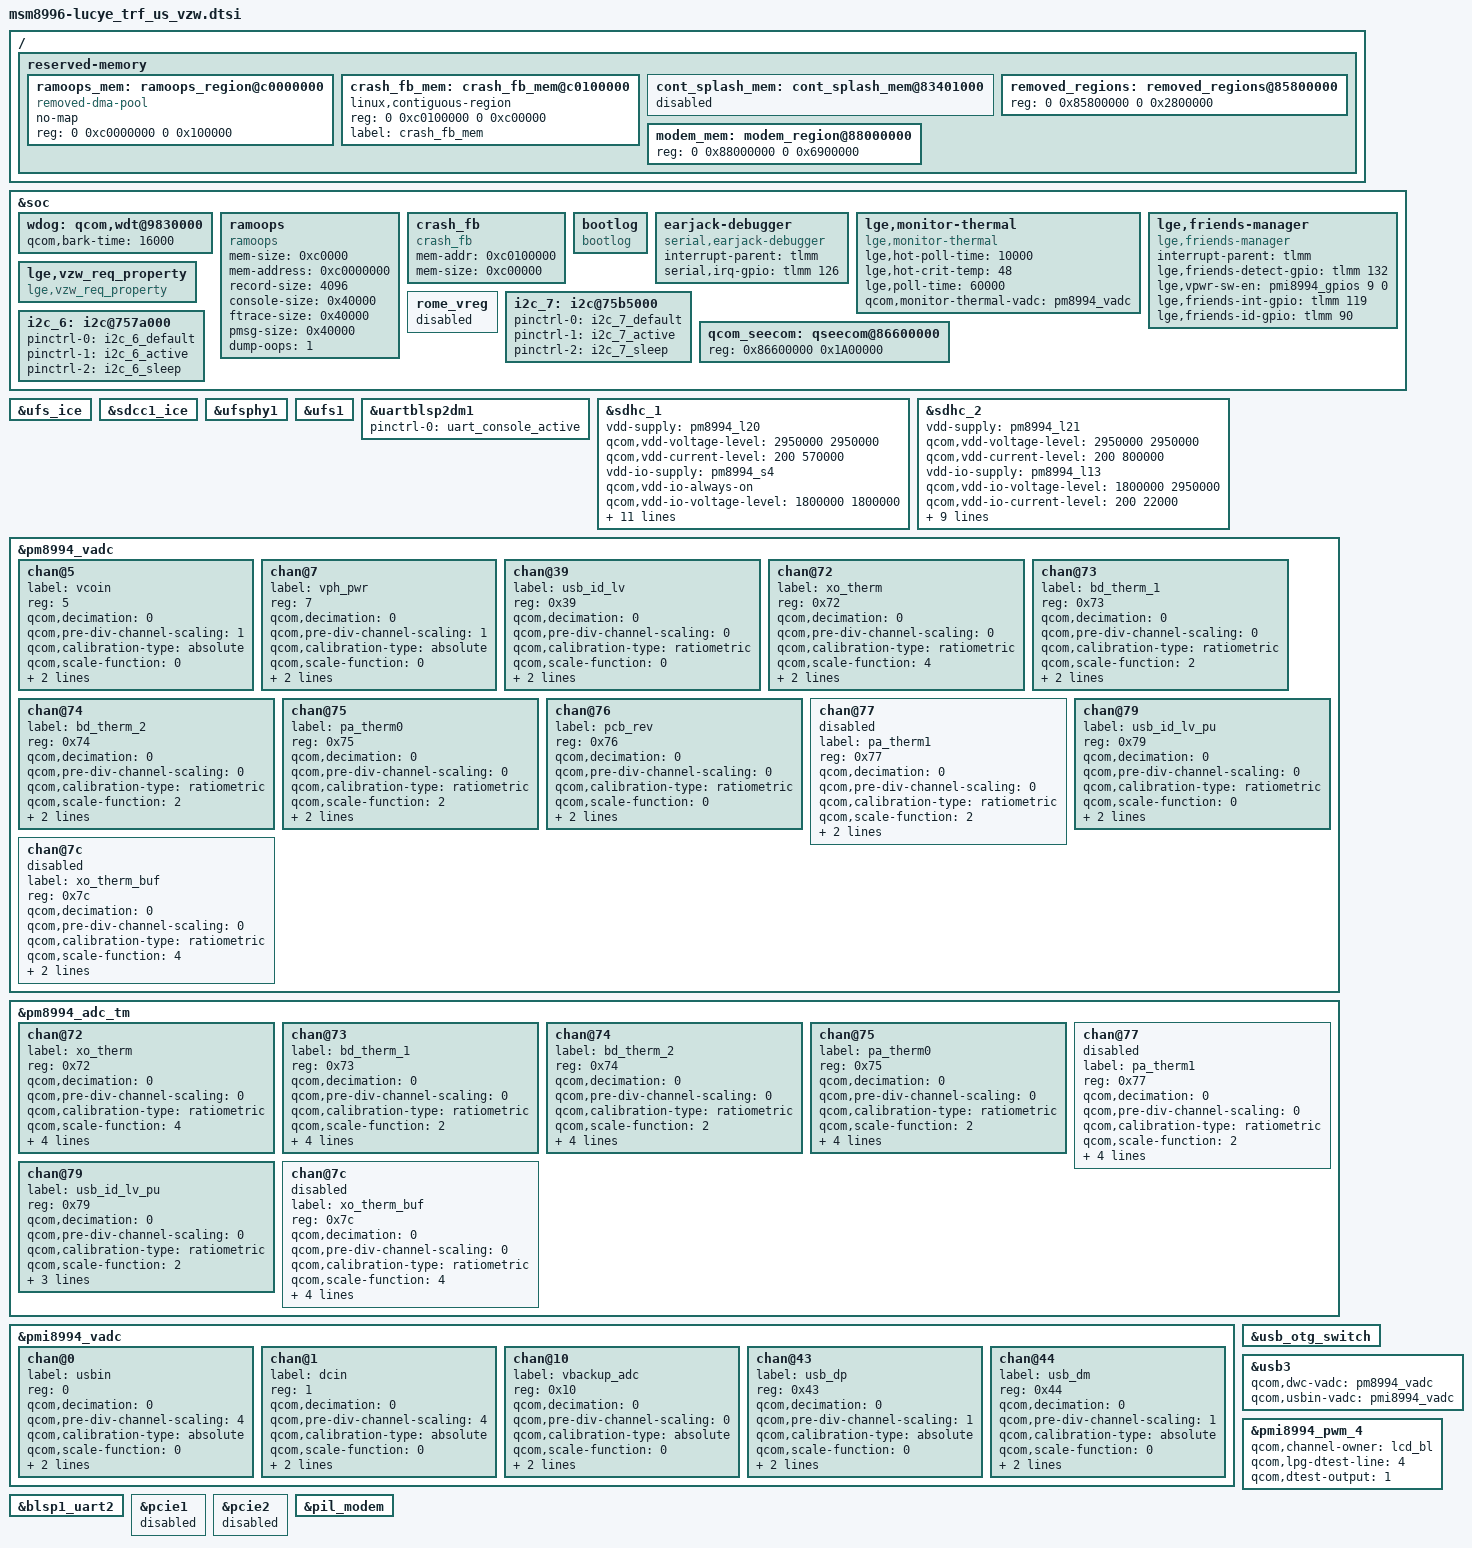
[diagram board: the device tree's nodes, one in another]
/* Copyright (c) 2015, The Linux Foundation. All rights reserved.
 *
 * This program is free software; you can redistribute it and/or modify
 * it under the terms of the GNU General Public License version 2 and
 * only version 2 as published by the Free Software Foundation.
 *
 * This program is distributed in the hope that it will be useful,
 * but WITHOUT ANY WARRANTY; without even the implied warranty of
 * MERCHANTABILITY or FITNESS FOR A PARTICULAR PURPOSE.  See the
 * GNU General Public License for more details.
 */

#include "msm8996-lucye_trf_us_vzw-pinctrl.dtsi"
#include "msm8996-lucye_trf_us_vzw-misc.dtsi"
#include "msm8996-lucye_trf_us_vzw-panel.dtsi"
#include "msm8996-lucye_trf_us_vzw-pm.dtsi"
#include "msm8996-lucye_trf_us_vzw-connectivity.dtsi"
#include "msm8996-lucye_trf_us_vzw-nfc.dtsi"
#include "msm8996-lucye_trf_us_vzw-hdmi.dtsi"
#include "msm8996-lucye_trf_us_vzw-fingerprint.dtsi"
#include "msm8996-lucye_trf_us_vzw-usb.dtsi"

/ {
	reserved-memory {
		ramoops_mem: ramoops_region@c0000000 {
			compatible = "removed-dma-pool";
			no-map;
			reg = <0 0xc0000000 0 0x100000>;
		};

		crash_fb_mem: crash_fb_mem@c0100000 {
			linux,contiguous-region;
			reg = <0 0xc0100000 0 0xc00000>;
			label = "crash_fb_mem";
		};

		cont_splash_mem: cont_splash_mem@83401000 {
			status = "disabled";
		};

		/delete-node/ dfps_data_mem@83400000;

		removed_regions: removed_regions@85800000 {
			reg = <0 0x85800000 0 0x2800000>;
		};

		modem_mem: modem_region@88000000 {
			reg = <0 0x88000000 0 0x6900000>;
		};
	};
};

&soc {
	wdog: qcom,wdt@9830000 {
		qcom,bark-time = <16000>;
	};

	ramoops {
		compatible = "ramoops";
		mem-size = <0xc0000>;
		mem-address = <0xc0000000>;
		record-size = <4096>;
		console-size = <0x40000>;
		ftrace-size = <0x40000>;
		pmsg-size = <0x40000>;
		dump-oops = <1>;
	};

	crash_fb {
		compatible = "crash_fb";
		mem-addr = <0xc0100000>;
		mem-size = <0xc00000>;
	};

	bootlog {
		compatible = "bootlog";
	};

	earjack-debugger {
		compatible = "serial,earjack-debugger";
		status = "ok";
		interrupt-parent = <&tlmm>;
		serial,irq-gpio = <&tlmm 126 0>;
	};

	lge,monitor-thermal {
		compatible = "lge,monitor-thermal";
		status = "ok";
		lge,hot-poll-time = <10000>;
		lge,hot-crit-temp = <48>;
		lge,poll-time = <60000>;
		qcom,monitor-thermal-vadc = <&pm8994_vadc>;
	};


	lge,friends-manager {
		compatible = "lge,friends-manager";
		status = "ok";
		interrupt-parent = <&tlmm>;
		lge,friends-detect-gpio = <&tlmm 132 0>;
		lge,vpwr-sw-en = <&pmi8994_gpios 9 0>;
		lge,friends-int-gpio = <&tlmm 119 0>;
		lge,friends-id-gpio = <&tlmm 90 0>;
//		pinctrl-names = "friends_active_pins","friends_sleep_pins";
//		pinctrl-0 = <&friends_detect_active>;
//		pinctrl-1 = <&friends_detect_sleep>;
	};

	lge,vzw_req_property {
		compatible = "lge,vzw_req_property";
		status = "ok";
	};

	rome_vreg: rome_vreg {
		status = "disabled";
	};

	/* I2C configuration */
/*	i2c_12: i2c@75ba000 {
		pinctrl-names = "default", "i2c_sleep";
		pinctrl-0 = <&i2c_12_default>;
		pinctrl-1 = <&i2c_12_sleep>;
	};
*/
	i2c_7: i2c@75b5000 {
		pinctrl-names = "default", "i2c_active", "i2c_sleep";
		pinctrl-0 = <&i2c_7_default>;
		pinctrl-1 = <&i2c_7_active>;
		pinctrl-2 = <&i2c_7_sleep>;
	};

	i2c_6: i2c@757a000 {
		pinctrl-names = "default", "i2c_active", "i2c_sleep";
		pinctrl-0 = <&i2c_6_default>;
		pinctrl-1 = <&i2c_6_active>;
		pinctrl-2 = <&i2c_6_sleep>;
	};

	/*delete QCT finger */
	/delete-node/ qcom,qbt1000;

	/delete-node/ qcom,cnss;
	/delete-node/ qcom,wil6210;

	qcom_seecom: qseecom@86600000 {
		reg = <0x86600000 0x1A00000>;
	};

};

&ufs_ice {
	status = "ok";
};

&sdcc1_ice {
        status = "ok";
};

&ufsphy1 {
	status = "ok";
};

&ufs1 {
	status = "ok";
};

&uartblsp2dm1 {
	status = "ok";
	pinctrl-names = "default";
	pinctrl-0 = <&uart_console_active>;
};

&sdhc_1 {
	vdd-supply = <&pm8994_l20>;
	qcom,vdd-voltage-level = <2950000 2950000>;
	qcom,vdd-current-level = <200 570000>;

	vdd-io-supply = <&pm8994_s4>;
	qcom,vdd-io-always-on;
	qcom,vdd-io-voltage-level = <1800000 1800000>;
	qcom,vdd-io-current-level = <110 325000>;

	pinctrl-names = "active", "sleep";
	pinctrl-0 = <&sdc1_clk_on &sdc1_cmd_on &sdc1_data_on &sdc1_rclk_on>;
	pinctrl-1 = <&sdc1_clk_off &sdc1_cmd_off &sdc1_data_off &sdc1_rclk_off>;

	qcom,clk-rates = <400000 20000000 25000000 50000000 96000000 192000000 384000000>;
	qcom,ice-clk-rates = <300000000>;
	qcom,nonremovable;
	qcom,bus-speed-mode = "HS400_1p8v", "HS200_1p8v", "DDR_1p8v";

	status = "ok";
};

&sdhc_2 {
	vdd-supply = <&pm8994_l21>;
	qcom,vdd-voltage-level = <2950000 2950000>;
	qcom,vdd-current-level = <200 800000>;

	vdd-io-supply = <&pm8994_l13>;
	qcom,vdd-io-voltage-level = <1800000 2950000>;
	qcom,vdd-io-current-level = <200 22000>;

	pinctrl-names = "active", "sleep";
	pinctrl-0 = <&sdc2_clk_on  &sdc2_cmd_on &sdc2_data_on &sdc2_cd_on>;
	pinctrl-1 = <&sdc2_clk_off &sdc2_cmd_off &sdc2_data_off &sdc2_cd_off>;

	qcom,clk-rates = <400000 20000000 25000000 50000000 100000000 200000000>;
	qcom,bus-speed-mode = "SDR12", "SDR25", "SDR50", "DDR50", "SDR104";

	/* Though Active-Low-H/W-logic is actually adopted in circuit-diagram,
	Logic-value is reversed in 3in2-socket not in 2in1-socket.
	1: Active-Low, 0: Active-High
	*/
	cd-gpios = <&tlmm 95 0x0>;

	status = "ok";
};

&pm8994_vadc {
	chan@5 {
		label = "vcoin";
		reg = <5>;
		qcom,decimation = <0>;
		qcom,pre-div-channel-scaling = <1>;
		qcom,calibration-type = "absolute";
		qcom,scale-function = <0>;
		qcom,hw-settle-time = <0>;
		qcom,fast-avg-setup = <0>;
	};

	chan@7 {
		label = "vph_pwr";
		reg = <7>;
		qcom,decimation = <0>;
		qcom,pre-div-channel-scaling = <1>;
		qcom,calibration-type = "absolute";
		qcom,scale-function = <0>;
		qcom,hw-settle-time = <0>;
		qcom,fast-avg-setup = <0>;
	};

	chan@39 {
		label = "usb_id_lv";
		reg = <0x39>;
		qcom,decimation = <0>;
		qcom,pre-div-channel-scaling = <0>;
		qcom,calibration-type = "ratiometric";
		qcom,scale-function = <0>;
		qcom,hw-settle-time = <5>;
		qcom,fast-avg-setup = <0>;
	};

        chan@72 {
		label = "xo_therm";
		reg = <0x72>;
		qcom,decimation = <0>;
		qcom,pre-div-channel-scaling = <0>;
		qcom,calibration-type = "ratiometric";
		qcom,scale-function = <4>;
		qcom,hw-settle-time = <2>;
		qcom,fast-avg-setup = <0>;
		status = "ok";
	};

	chan@73 {
		label = "bd_therm_1";
		reg = <0x73>;
		qcom,decimation = <0>;
		qcom,pre-div-channel-scaling = <0>;
		qcom,calibration-type = "ratiometric";
		qcom,scale-function = <2>;
		qcom,hw-settle-time = <2>;
		qcom,fast-avg-setup = <0>;
		status = "ok";
	};

	chan@74 {
		label = "bd_therm_2";
		reg = <0x74>;
		qcom,decimation = <0>;
		qcom,pre-div-channel-scaling = <0>;
		qcom,calibration-type = "ratiometric";
		qcom,scale-function = <2>;
		qcom,hw-settle-time = <2>;
		qcom,fast-avg-setup = <0>;
		status = "ok";
	};

	chan@75 {
		label = "pa_therm0";
		reg = <0x75>;
		qcom,decimation = <0>;
		qcom,pre-div-channel-scaling = <0>;
		qcom,calibration-type = "ratiometric";
		qcom,scale-function = <2>;
		qcom,hw-settle-time = <2>;
		qcom,fast-avg-setup = <0>;
		status = "ok";
	};

	chan@76 {
		label = "pcb_rev";
		reg = <0x76>;
		qcom,decimation = <0>;
		qcom,pre-div-channel-scaling = <0>;
		qcom,calibration-type = "ratiometric";
		qcom,scale-function = <0>;
		qcom,hw-settle-time = <1>;
		qcom,fast-avg-setup = <0>;
	};

	chan@77 {
		label = "pa_therm1";
		reg = <0x77>;
		qcom,decimation = <0>;
		qcom,pre-div-channel-scaling = <0>;
		qcom,calibration-type = "ratiometric";
		qcom,scale-function = <2>;
		qcom,hw-settle-time = <2>;
		qcom,fast-avg-setup = <0>;
		status = "disabled";
	};

	chan@79 {
		label = "usb_id_lv_pu";
		reg = <0x79>;
		qcom,decimation = <0>;
		qcom,pre-div-channel-scaling = <0>;
		qcom,calibration-type = "ratiometric";
		qcom,scale-function = <0>;
		qcom,hw-settle-time = <5>;
		qcom,fast-avg-setup = <0>;
	};

	chan@7c {
		label = "xo_therm_buf";
		reg = <0x7c>;
		qcom,decimation = <0>;
		qcom,pre-div-channel-scaling = <0>;
		qcom,calibration-type = "ratiometric";
		qcom,scale-function = <4>;
		qcom,hw-settle-time = <2>;
		qcom,fast-avg-setup = <0>;
		status = "disabled";
	};
};

&pm8994_adc_tm {
	chan@72 {
		label = "xo_therm";
		reg = <0x72>;
		qcom,decimation = <0>;
		qcom,pre-div-channel-scaling = <0>;
		qcom,calibration-type = "ratiometric";
		qcom,scale-function = <4>;
		qcom,hw-settle-time = <2>;
		qcom,fast-avg-setup = <0>;
		qcom,btm-channel-number = <0x72>;
		qcom,thermal-node;
		status = "ok";
	};

	chan@73 {
		label = "bd_therm_1";
		reg = <0x73>;
		qcom,decimation = <0>;
		qcom,pre-div-channel-scaling = <0>;
		qcom,calibration-type = "ratiometric";
		qcom,scale-function = <2>;
		qcom,hw-settle-time = <2>;
		qcom,fast-avg-setup = <0>;
		qcom,btm-channel-number = <0x48>;
		qcom,thermal-node;
		status = "ok";
	};

	chan@74 {
		label = "bd_therm_2";
		reg = <0x74>;
		qcom,decimation = <0>;
		qcom,pre-div-channel-scaling = <0>;
		qcom,calibration-type = "ratiometric";
		qcom,scale-function = <2>;
		qcom,hw-settle-time = <2>;
		qcom,fast-avg-setup = <0>;
		qcom,btm-channel-number = <0x68>;
		qcom,thermal-node;
		status = "ok";
	};

	chan@75 {
		label = "pa_therm0";
		reg = <0x75>;
		qcom,decimation = <0>;
		qcom,pre-div-channel-scaling = <0>;
		qcom,calibration-type = "ratiometric";
		qcom,scale-function = <2>;
		qcom,hw-settle-time = <2>;
		qcom,fast-avg-setup = <0>;
		qcom,btm-channel-number = <0x70>;
		qcom,thermal-node;
		status = "ok";
	};

	chan@77 {
		label = "pa_therm1";
		reg = <0x77>;
		qcom,decimation = <0>;
		qcom,pre-div-channel-scaling = <0>;
		qcom,calibration-type = "ratiometric";
		qcom,scale-function = <2>;
		qcom,hw-settle-time = <2>;
		qcom,fast-avg-setup = <0>;
		qcom,btm-channel-number = <0x78>;
		qcom,thermal-node;
		status = "disabled";
	};

	chan@79 {
		label = "usb_id_lv_pu";
		reg = <0x79>;
		qcom,decimation = <0>;
		qcom,pre-div-channel-scaling = <0>;
		qcom,calibration-type = "ratiometric";
		qcom,scale-function = <2>;
		qcom,hw-settle-time = <2>;
		qcom,fast-avg-setup = <3>;
		qcom,btm-channel-number = <0x80>;
	};

	chan@7c {
		label = "xo_therm_buf";
		reg = <0x7c>;
		qcom,decimation = <0>;
		qcom,pre-div-channel-scaling = <0>;
		qcom,calibration-type = "ratiometric";
		qcom,scale-function = <4>;
		qcom,hw-settle-time = <2>;
		qcom,fast-avg-setup = <0>;
		qcom,btm-channel-number = <0x88>;
		qcom,thermal-node;
		status = "disabled";
	};
};

&pmi8994_vadc {
	chan@0 {
		label = "usbin";
		reg = <0>;
		qcom,decimation = <0>;
		qcom,pre-div-channel-scaling = <4>;
		qcom,calibration-type = "absolute";
		qcom,scale-function = <0>;
		qcom,hw-settle-time = <0>;
		qcom,fast-avg-setup = <0>;
	};

	chan@1 {
		label = "dcin";
		reg = <1>;
		qcom,decimation = <0>;
		qcom,pre-div-channel-scaling = <4>;
		qcom,calibration-type = "absolute";
		qcom,scale-function = <0>;
		qcom,hw-settle-time = <0>;
		qcom,fast-avg-setup = <0>;
	};

	chan@10 {
		label = "vbackup_adc";
		reg = <0x10>;
		qcom,decimation = <0>;
		qcom,pre-div-channel-scaling = <0>;
		qcom,calibration-type = "absolute";
		qcom,scale-function = <0>;
		qcom,hw-settle-time = <1>;
		qcom,fast-avg-setup = <2>;
	};

	chan@43 {
		label = "usb_dp";
		reg = <0x43>;
		qcom,decimation = <0>;
		qcom,pre-div-channel-scaling = <1>;
		qcom,calibration-type = "absolute";
		qcom,scale-function = <0>;
		qcom,hw-settle-time = <0>;
		qcom,fast-avg-setup = <0>;
	};

	chan@44 {
		label = "usb_dm";
		reg = <0x44>;
		qcom,decimation = <0>;
		qcom,pre-div-channel-scaling = <1>;
		qcom,calibration-type = "absolute";
		qcom,scale-function = <0>;
		qcom,hw-settle-time = <0>;
		qcom,fast-avg-setup = <0>;
	};
};

&usb_otg_switch {
	status = "okay";
};

&usb3 {
	status = "ok";
	qcom,dwc-vadc = <&pm8994_vadc>;
	qcom,usbin-vadc = <&pmi8994_vadc>;
};

&pmi8994_pwm_4 {
	qcom,channel-owner = "lcd_bl";
	qcom,lpg-dtest-line = <4>;
	qcom,dtest-output = <1>;
	status = "okay";
};

&blsp1_uart2 {
	status = "ok";
};

&pcie1 {
       status = "disabled";
};

&pcie2 {
       status = "disabled";
};

&pil_modem {
       /delete-property/ qcom,mx-spike-wa;
};
